VERSION ""

NS_ :

BS_:

BU_: SygnalMCM UserApplication

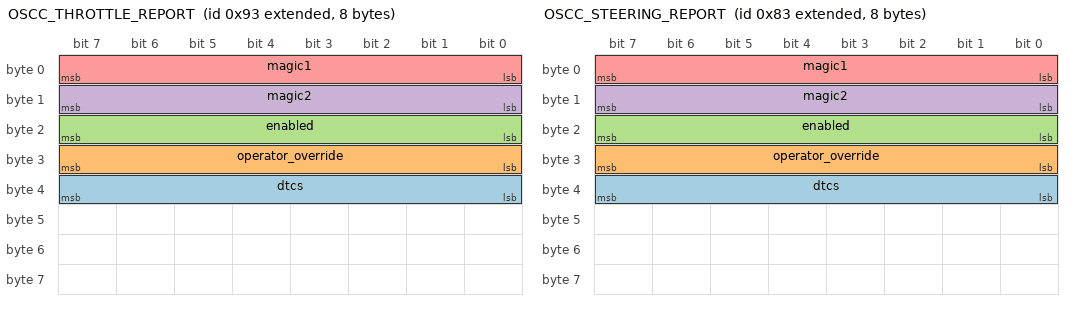
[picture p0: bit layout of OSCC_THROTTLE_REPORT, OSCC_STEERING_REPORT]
BO_ 2147483795 OSCC_THROTTLE_REPORT: 8 SygnalMCM
 SG_ dtcs : 32|8@1+ (1,0) [0|0] ""  UserApplication
 SG_ operator_override : 24|8@1+ (1,0) [0|0] ""  UserApplication
 SG_ enabled : 16|8@1+ (1,0) [0|0] ""  UserApplication
 SG_ magic2 : 8|8@1+ (1,0) [204|204] ""  UserApplication
 SG_ magic1 : 0|8@1+ (1,0) [5|5] ""  UserApplication

BO_ 2147483779 OSCC_STEERING_REPORT: 8 SygnalMCM
 SG_ dtcs : 32|8@1+ (1,0) [0|0] ""  UserApplication
 SG_ operator_override : 24|8@1+ (1,0) [0|0] ""  UserApplication
 SG_ enabled : 16|8@1+ (1,0) [0|0] ""  UserApplication
 SG_ magic2 : 8|8@1+ (1,0) [204|204] ""  UserApplication
 SG_ magic1 : 0|8@1+ (1,0) [5|5] ""  UserApplication

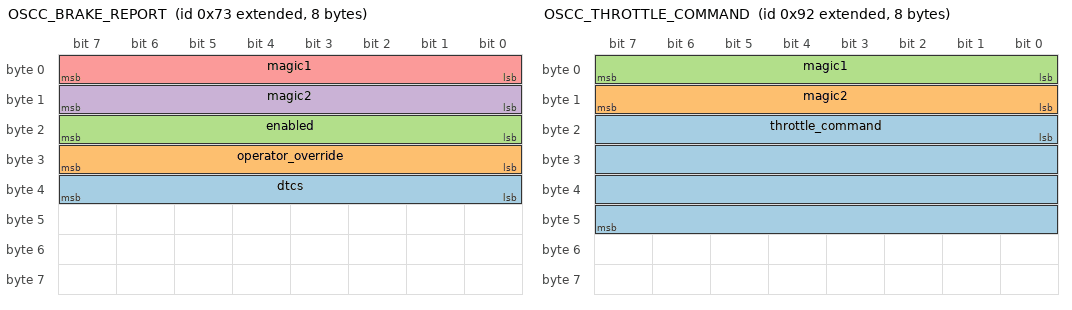
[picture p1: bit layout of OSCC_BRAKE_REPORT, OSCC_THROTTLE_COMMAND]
BO_ 2147483763 OSCC_BRAKE_REPORT: 8 SygnalMCM
 SG_ dtcs : 32|8@1+ (1,0) [0|0] ""  UserApplication
 SG_ operator_override : 24|8@1+ (1,0) [0|0] ""  UserApplication
 SG_ enabled : 16|8@1+ (1,0) [0|0] ""  UserApplication
 SG_ magic2 : 8|8@1+ (1,0) [204|204] ""  UserApplication
 SG_ magic1 : 0|8@1+ (1,0) [5|5] ""  UserApplication

BO_ 2147483794 OSCC_THROTTLE_COMMAND: 8 UserApplication
 SG_ throttle_command : 16|32@1- (1,0) [0|1] ""  SygnalMCM
 SG_ magic2 : 8|8@1+ (1,0) [204|204] ""  SygnalMCM
 SG_ magic1 : 0|8@1+ (1,0) [5|5] ""  SygnalMCM

BO_ 2147483793 OSCC_THROTTLE_DISABLE: 8 UserApplication
 SG_ magic2 : 8|8@1+ (1,0) [204|204] ""  SygnalMCM
 SG_ magic1 : 0|8@1+ (1,0) [5|5] ""  SygnalMCM

BO_ 2147483792 OSCC_THROTTLE_ENABLE: 8 UserApplication
 SG_ magic2 : 8|8@1+ (1,0) [204|204] ""  SygnalMCM
 SG_ magic1 : 0|8@1+ (1,0) [5|5] ""  SygnalMCM

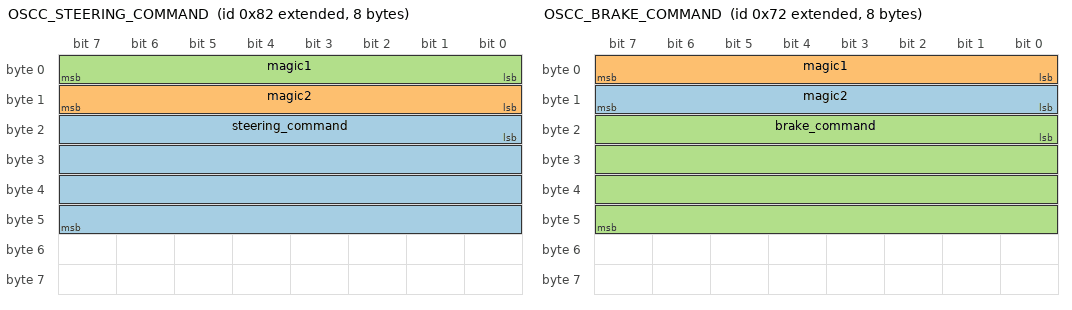
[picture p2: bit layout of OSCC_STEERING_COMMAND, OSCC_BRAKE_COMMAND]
BO_ 2147483778 OSCC_STEERING_COMMAND: 8 UserApplication
 SG_ steering_command : 16|32@1- (1,0) [-1|1] ""  SygnalMCM
 SG_ magic2 : 8|8@1+ (1,0) [204|204] ""  SygnalMCM
 SG_ magic1 : 0|8@1+ (1,0) [5|5] ""  SygnalMCM

BO_ 2147483777 OSCC_STEERING_DISABLE: 8 UserApplication
 SG_ magic2 : 8|8@1+ (1,0) [204|204] ""  SygnalMCM
 SG_ magic1 : 0|8@1+ (1,0) [5|5] ""  SygnalMCM

BO_ 2147483776 OSCC_STEERING_ENABLE: 8 UserApplication
 SG_ magic2 : 8|8@1+ (1,0) [204|204] ""  SygnalMCM
 SG_ magic1 : 0|8@1+ (1,0) [5|5] ""  SygnalMCM

BO_ 2147483762 OSCC_BRAKE_COMMAND: 8 UserApplication
 SG_ magic2 : 8|8@1+ (1,0) [204|204] ""  SygnalMCM
 SG_ magic1 : 0|8@1+ (1,0) [5|5] ""  SygnalMCM
 SG_ brake_command : 16|32@1- (1,0) [0|1] ""  SygnalMCM

BO_ 2147483761 OSCC_BRAKE_DISABLE: 8 UserApplication
 SG_ magic2 : 8|8@1+ (1,0) [204|204] ""  SygnalMCM
 SG_ magic1 : 0|8@1+ (1,0) [5|5] ""  SygnalMCM

BO_ 2147483760 OSCC_BRAKE_ENABLE: 8 UserApplication
 SG_ magic2 : 8|8@1+ (1,0) [204|204] ""  SygnalMCM
 SG_ magic1 : 0|8@1+ (1,0) [5|5] ""  SygnalMCM

BA_DEF_ BO_  "VFrameFormat" ENUM  "StandardCAN","ExtendedCAN","reserved","J1939PG";
BA_DEF_  "ProtocolType" STRING ;
BA_DEF_  "BusType" STRING ;
BA_DEF_DEF_  "VFrameFormat" "J1939PG";
BA_DEF_DEF_  "ProtocolType" "J1939";
BA_DEF_DEF_  "BusType" "CAN";
SIG_VALTYPE_ 2147483794 throttle_command : 1;
SIG_VALTYPE_ 2147483778 steering_command : 1;
SIG_VALTYPE_ 2147483762 brake_command : 1;
